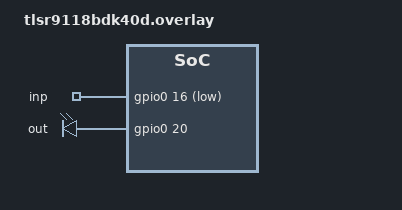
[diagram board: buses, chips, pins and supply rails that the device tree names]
/ {
	/* Short TL_Key1 (J20 pin 11) to ground (J20 pin 25-35) */
	key_pool {
		compatible = "gpio-keys";

		inp {
			gpios = <&gpio0 16 (GPIO_ACTIVE_LOW | GPIO_PULL_UP)>,
					<&gpio0 15 (GPIO_ACTIVE_LOW | GPIO_PULL_UP)>;
		};
	};

	led_pool{
		compatible = "gpio-leds";

		out {
			gpios = <&gpio0 20 GPIO_ACTIVE_HIGH>;
		};
	};
};
